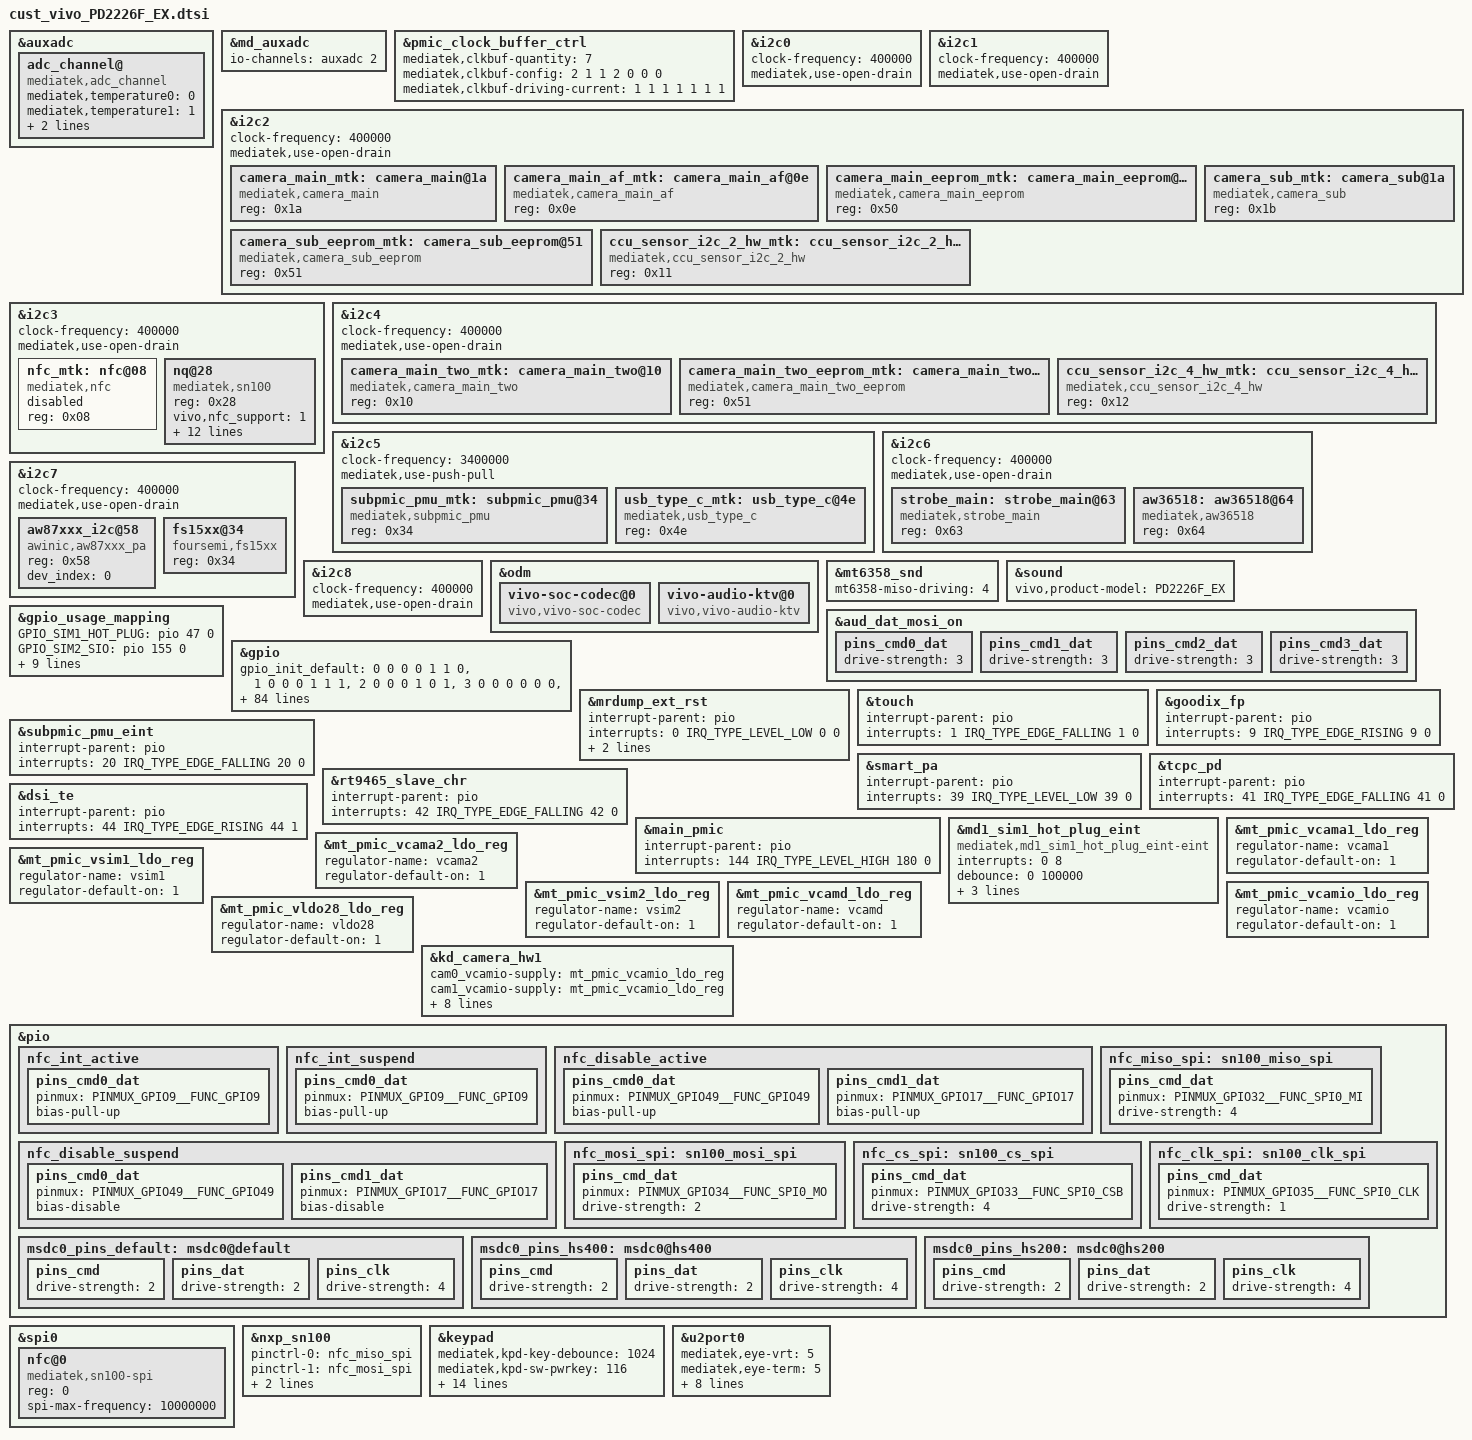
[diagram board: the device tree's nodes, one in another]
/*
 * Generated by MTK SP DrvGen Version: 3.5.160809 for MT6768.
 * 2022-04-25 19:38:39
 * Do Not Modify The File.
 * Copyright Mediatek Inc. (c) 2016.
*/

/*************************
 * ADC DTSI File
*************************/

&auxadc {
	adc_channel@ {
		compatible = "mediatek,adc_channel";
		mediatek,temperature0 = <0>;
		mediatek,temperature1 = <1>;
		mediatek,adc_fdd_rf_params_dynamic_custom_ch = <2>;
		status = "okay";
	};
};
&md_auxadc {
	io-channels = <&auxadc 2>;
};


/*************************
 * CLK_BUF DTSI File
*************************/

&pmic_clock_buffer_ctrl {
	mediatek,clkbuf-quantity = <7>;
	mediatek,clkbuf-config = <2 1 1 2 0 0 0>;
	mediatek,clkbuf-driving-current = <1 1 1 1 1 1 1>;
	status = "okay";
};


/*************************
 * I2C DTSI File
*************************/

&i2c0 {
	#address-cells = <1>;
	#size-cells = <0>;
	clock-frequency = <400000>;
	mediatek,use-open-drain;
};

&i2c1 {
	#address-cells = <1>;
	#size-cells = <0>;
	clock-frequency = <400000>;
	mediatek,use-open-drain;
};

&i2c2 {
	#address-cells = <1>;
	#size-cells = <0>;
	clock-frequency = <400000>;
	mediatek,use-open-drain;
	camera_main_mtk:camera_main@1a {
		compatible = "mediatek,camera_main";
		reg = <0x1a>;
		status = "okay";
	};
	camera_main_af_mtk:camera_main_af@0e {
		compatible = "mediatek,camera_main_af";
		reg = <0x0e>;
		status = "okay";
	};
	camera_main_eeprom_mtk:camera_main_eeprom@50 {
		compatible = "mediatek,camera_main_eeprom";
		reg = <0x50>;
		status = "okay";
	};
	camera_sub_mtk:camera_sub@1a {
		compatible = "mediatek,camera_sub";
		reg = <0x1b>;
		status = "okay";
	};
	camera_sub_eeprom_mtk:camera_sub_eeprom@51 {
		compatible = "mediatek,camera_sub_eeprom";
		reg = <0x51>;
		status = "okay";
	};

	ccu_sensor_i2c_2_hw_mtk:ccu_sensor_i2c_2_hw@11 {
		compatible = "mediatek,ccu_sensor_i2c_2_hw";
		reg = <0x11>;
		status = "okay";
	};

};

&i2c3 {
	#address-cells = <1>;
	#size-cells = <0>;
	clock-frequency = <400000>;
	mediatek,use-open-drain;
	nfc_mtk:nfc@08 {
		compatible = "mediatek,nfc";
		reg = <0x08>;
		status = "disable";
	};

};

&i2c4 {
	#address-cells = <1>;
	#size-cells = <0>;
	clock-frequency = <400000>;
	mediatek,use-open-drain;
	camera_main_two_mtk:camera_main_two@10 {
		compatible = "mediatek,camera_main_two";
		reg = <0x10>;
		status = "okay";
	};
	camera_main_two_eeprom_mtk:camera_main_two_eeprom@51 {
		compatible = "mediatek,camera_main_two_eeprom";
		reg = <0x51>;
		status = "okay";
	};

	ccu_sensor_i2c_4_hw_mtk:ccu_sensor_i2c_4_hw@12 {
		compatible = "mediatek,ccu_sensor_i2c_4_hw";
		reg = <0x12>;
		status = "okay";
	};

};

&i2c5 {
	#address-cells = <1>;
	#size-cells = <0>;
	clock-frequency = <3400000>;
	mediatek,use-push-pull;
	subpmic_pmu_mtk:subpmic_pmu@34 {
		compatible = "mediatek,subpmic_pmu";
		reg = <0x34>;
		status = "okay";
	};

	usb_type_c_mtk:usb_type_c@4e {
		compatible = "mediatek,usb_type_c";
		reg = <0x4e>;
		status = "okay";
	};

};

&i2c6 {
	#address-cells = <1>;
	#size-cells = <0>;
	clock-frequency = <400000>;
	mediatek,use-open-drain;
    strobe_main: strobe_main@63 {   //添加I2C设备
        compatible = "mediatek,strobe_main";
        reg = <0x63>;
        status = "okay";
    };
    aw36518: aw36518@64 {   //添加I2C设备
        compatible = "mediatek,aw36518";
        reg = <0x64>;
        status = "okay";
    };
};

&i2c7 {
	#address-cells = <1>;
	#size-cells = <0>;
	clock-frequency = <400000>;
	mediatek,use-open-drain;
};

&i2c8 {
	#address-cells = <1>;
	#size-cells = <0>;
	clock-frequency = <400000>;
	mediatek,use-open-drain;
};

/* xudong add for audio start */

&odm {
	vivo-soc-codec@0 {
		compatible = "vivo,vivo-soc-codec";
		status = "okay";
	};

	vivo-audio-ktv@0 {
		compatible = "vivo,vivo-audio-ktv";
		status = "okay";
	};
};

&i2c7 {
	aw87xxx_i2c@58 {
		compatible = "awinic,aw87xxx_pa";
		reg = <0x58>;
		dev_index= <0>;
		status = "okay";
	};
	fs15xx@34 {
 		compatible = "foursemi,fs15xx";
 		reg = <0x34>;
 		status = "okay";
 	};
};

/* yanghen add for audio end */
/* Audio add for modify miso driving */
/* 4:4mA, 8:8mA, 12:12mA, 16:16mA */
&mt6358_snd {
	mt6358-miso-driving = <4>;
};

&sound {
    vivo,product-model = "PD2226F_EX";
};

&aud_dat_mosi_on {
	pins_cmd0_dat {
		drive-strength = <3>;
	};
	pins_cmd1_dat {
		drive-strength = <3>;
	};
	pins_cmd2_dat {
		drive-strength = <3>;
	};
	pins_cmd3_dat {
		drive-strength = <3>;
	};
};
/* Audio add End */
/*************************
 * GPIO DTSI File
*************************/

&gpio_usage_mapping {
	GPIO_SIM1_HOT_PLUG = <&pio 47 0>; //GPIO_SIM1_HOT_PLUG gpio46
	GPIO_SIM2_SIO = <&pio 155 0>;
	GPIO_SIM2_SRST = <&pio 156 0>;
	GPIO_SIM2_SCLK = <&pio 157 0>;
	GPIO_SIM1_SCLK = <&pio 172 0>;
	GPIO_SIM1_SRST = <&pio 173 0>;
	GPIO_SIM1_SIO = <&pio 174 0>;
	GPIO_FDD_BAND_SUPPORT_DETECT_1ST_PIN = <&pio 23 0>;
	GPIO_FDD_BAND_SUPPORT_DETECT_2ND_PIN = <&pio 21 0>;
	GPIO_FDD_BAND_SUPPORT_DETECT_3RD_PIN = <&pio 10 0>;
	GPIO_FDD_BAND_SUPPORT_DETECT_4TH_PIN = <&pio 29 0>;
};

&gpio{
	gpio_init_default = <0 0 0 0 1 1 0>,
		<1 0 0 0 1 1 1>,
		<2 0 0 0 1 0 1>,
		<3 0 0 0 0 0 0>,//sub chg-int
		<4 0 0 0 1 0 0>,
		<5 0 0 0 1 1 0>,
		<6 0 0 0 0 0 0>,//main chg-int
		<7 0 0 0 1 0 0>,
		<8 0 0 0 1 0 0>,
		<9 0 0 0 1 0 0>,
		<10 0 0 0 1 1 0>,
		<11 1 0 0 1 0 0>,
		<12 0 0 0 0 0 1>,
		<13 2 0 0 0 0 0>,
		<14 2 1 0 0 0 0>,
		<15 2 1 0 0 0 0>,
		<16 2 1 0 0 0 0>,
		<17 0 0 0 1 0 1>,
		<18 0 0 0 1 1 1>,
		<19 0 0 0 1 1 1>,
		<20 0 0 0 1 1 1>,
		<21 0 0 0 1 1 0>,
		<22 0 1 0 1 0 0>,//sub chg enable
		<23 0 0 0 1 1 0>,
		<24 0 1 0 1 1 1>,//cam0 dvdd_en
		<25 0 1 0 1 0 0>,
		<26 0 1 0 1 0 0>,
		<27 0 1 0 1 0 0>,
		<28 0 1 0 1 0 0>,
		<29 0 0 0 1 1 0>,
		<30 0 1 0 0 0 0>,
		<31 0 0 0 1 0 0>,
		<32 7 1 0 0 0 0>,
		<33 7 0 0 1 0 0>,
		<34 7 0 0 1 0 0>,
		<35 7 0 0 1 0 0>,
		<36 2 1 0 0 0 0>,
		<37 2 1 0 0 0 0>,
		<38 2 1 0 0 0 0>,
		<39 0 0 0 1 1 1>,
		<40 2 0 0 1 0 0>,
		<41 0 0 0 1 1 1>,//cc logic int-gpio
		<42 0 0 0 1 1 1>,
		<43 1 1 0 0 0 0>,
		<44 1 0 0 1 0 0>,
		<45 0 1 0 0 0 0>,
		<46 0 0 0 0 0 0>,
		<47 1 0 0 0 0 1>,
		<48 1 0 0 1 1 1>,
		<49 1 0 0 1 1 1>,
		<50 1 0 0 0 0 1>,
		<51 1 0 0 0 0 1>,
		<52 1 0 0 1 0 0>,
		<53 1 0 0 1 0 0>,
		<54 1 0 0 1 0 0>,
		<55 1 0 0 1 0 0>,
		<56 1 0 0 1 0 0>,
		<57 1 0 0 1 0 0>,
		<58 0 0 0 1 0 0>,
		<59 1 0 0 1 0 0>,
		<60 1 0 0 1 0 0>,
		<61 1 0 0 1 0 0>,
		<62 1 0 0 1 0 0>,
		<63 1 0 0 1 0 0>,
		<64 1 0 0 1 0 0>,
		<65 1 0 0 1 0 0>,
		<66 1 0 0 1 0 0>,
		<67 1 0 0 1 0 0>,
		<68 1 0 0 1 0 0>,
		<69 1 0 0 1 0 0>,
		<70 1 0 0 1 0 0>,
		<71 1 0 0 1 0 0>,
		<72 1 0 0 1 0 0>,
		<73 1 0 0 1 0 0>,
		<74 1 0 0 1 0 0>,
		<75 1 0 0 1 0 0>,
		<76 1 0 0 1 0 0>,
		<77 1 0 0 1 0 0>,
		<78 0 0 0 1 1 0>,
		<79 0 0 0 1 0 0>,
		<80 0 0 0 1 0 0>,
		<81 2 0 0 1 1 1>,
		<82 1 0 0 1 1 1>,
		<83 1 0 0 1 1 1>,
		<84 2 0 0 1 1 1>,
		<85 2 0 0 1 0 0>,
		<86 2 1 0 0 0 0>,
		<87 2 1 0 0 0 0>,
		<88 2 1 0 0 0 0>,
		<89 1 0 0 0 0 1>,//flash i2c6 scl rear
		<90 1 0 0 0 0 1>,//flash i2c6 sda rear
		<91 0 0 0 1 1 0>,
		<92 0 1 0 1 1 1>,//CAM_FLASH_TORCH
		<93 1 0 0 1 1 0>,
		<94 0 1 0 0 0 0>,
		<95 1 0 0 1 1 0>,
		<96 1 1 0 0 0 0>,
		<97 0 1 0 0 0 0>,
		<98 0 1 0 0 0 0>,
		<99 1 1 0 0 0 0>,
		<100 1 0 0 1 0 1>,//cam0 mclk1
		<101 0 1 0 0 0 0>,
		<102 0 1 0 1 1 1>,//cam0 rst
		<103 1 0 0 0 0 1>,//cam0,1 i2c2 scl
		<104 1 0 0 0 0 1>,//cam0,1 i2c2 sda
		<105 1 0 0 0 0 1>,//cam2 i2c4 scl
		<106 1 0 0 0 0 1>,//cam2 i2c4 sda
		<107 0 1 0 0 0 0>,
		<108 1 0 0 1 0 1>,//cam1 mclk2
		<109 0 1 0 1 1 1>,//cam1 rst
		<110 0 1 0 0 0 0>,
		<111 1 0 0 1 0 1>,//cam2 mclk3
		<112 0 1 0 1 1 1>,//cam2 rst
		<113 0 0 0 1 0 0>,
		<114 0 0 0 1 0 0>,
		<115 0 0 0 1 0 0>,
		<116 0 0 0 1 0 0>,
		<117 0 0 0 1 0 0>,
		<118 0 0 0 1 0 0>,
		<119 0 0 0 1 0 0>,
		<120 0 0 0 1 0 0>,
		<121 0 0 0 1 0 0>,
		<134 1 0 0 1 0 1>,
		<135 1 1 0 0 0 0>,
		<136 1 1 0 0 0 0>,
		<137 1 1 0 0 0 0>,
		<138 1 1 0 0 0 0>,
		<139 1 1 0 0 0 0>,
		<140 1 0 0 1 0 0>,
		<141 1 0 0 1 0 0>,
		<142 1 0 0 1 0 0>,
		<143 1 0 0 1 0 0>,
		<144 1 0 0 1 0 0>,
		<145 1 1 0 0 0 0>,
		<146 1 1 0 0 0 0>,
		<147 1 1 0 0 0 0>,
		<148 1 1 0 0 0 0>,
		<149 1 1 0 0 0 0>,
		<150 0 1 0 1 1 1>,//cam0,1,2 avdd_en
		<151 0 1 0 0 0 0>,//usb oe
		<152 0 1 0 0 0 0>,//GPIO_FLASH_EN
		<153 0 1 0 0 0 0>,//GPIO_FLASH_STROBE
		<154 1 1 0 0 0 0>,
		<155 1 0 0 1 1 0>,
		<156 1 1 0 0 0 0>,
		<157 1 1 0 0 0 0>,
		<158 0 1 1 0 0 0>,//BATID_CTRL
		<159 0 1 0 0 0 0>,//usb sel
		<160 0 0 0 1 1 0>,
		<161 1 0 0 1 1 1>,
		<162 1 0 0 1 1 1>,
		<163 1 0 0 1 1 1>,
		<164 1 0 0 1 1 1>,
		<165 0 1 0 0 0 0>,
		<166 0 0 0 1 1 0>,
		<167 1 0 0 1 0 0>,
		<168 1 0 0 1 0 0>,
		<169 0 1 0 0 0 0>,
		<170 1 0 0 1 1 1>,
		<171 1 1 0 0 0 1>,
		<172 1 1 0 0 0 0>,
		<173 1 1 0 0 0 0>,
		<174 1 0 0 1 1 0>,
		<175 1 0 0 1 1 1>,
		<176 1 0 0 1 1 1>,
		<178 0 0 0 1 1 0>,
		<179 0 0 0 1 1 0>,
		<180 0 0 0 1 0 0>,
		<181 0 0 0 1 0 0>,
		<182 0 0 0 1 0 0>,
		<183 0 0 0 1 0 0>,
		<184 0 0 0 1 0 0>,
		<185 0 0 0 1 0 0>,
		<186 0 0 0 1 0 0>;
};


/*************************
 * EINT DTSI File
*************************/

#include <dt-bindings/interrupt-controller/irq.h>
#include <dt-bindings/interrupt-controller/arm-gic.h>

&mrdump_ext_rst {
	interrupt-parent = <&pio>;
	interrupts = <0 IRQ_TYPE_LEVEL_LOW 0 0>;
	deb-gpios = <&pio 0 0>;
	debounce = <512000>;
	status = "okay";
};

&touch {
	interrupt-parent = <&pio>;
	interrupts = <1 IRQ_TYPE_EDGE_FALLING 1 0>;
	status = "okay";
};

&goodix_fp {
	interrupt-parent = <&pio>;
	interrupts = <9 IRQ_TYPE_EDGE_RISING 9 0>;
	status = "okay";
};

&subpmic_pmu_eint {
	interrupt-parent = <&pio>;
	interrupts = <20 IRQ_TYPE_EDGE_FALLING 20 0>;
	status = "okay";
};

&smart_pa {
	interrupt-parent = <&pio>;
	interrupts = <39 IRQ_TYPE_LEVEL_LOW 39 0>;
	status = "okay";
};

&tcpc_pd {
	interrupt-parent = <&pio>;
	interrupts = <41 IRQ_TYPE_EDGE_FALLING 41 0>;
	status = "okay";
};

&rt9465_slave_chr {
	interrupt-parent = <&pio>;
	interrupts = <42 IRQ_TYPE_EDGE_FALLING 42 0>;
	status = "okay";
};

&dsi_te {
	interrupt-parent = <&pio>;
	interrupts = <44 IRQ_TYPE_EDGE_RISING 44 1>;
	status = "okay";
};

&main_pmic {
	interrupt-parent = <&pio>;
	interrupts = <144 IRQ_TYPE_LEVEL_HIGH 180 0>;
	status = "okay";
};



/*************************
 * MD1_EINT DTSI File
*************************/

&md1_sim1_hot_plug_eint {
	compatible = "mediatek,md1_sim1_hot_plug_eint-eint";
	interrupts = <0 8>;
	debounce = <0 100000>;
	dedicated = <0 0>;
	src_pin = <0 1>;
	sockettype = <0 0>;
	status = "okay";
};




/*************************
 * PMIC DTSI File
*************************/

&mt_pmic_vcama1_ldo_reg {
	regulator-name = "vcama1";
	regulator-default-on = <1>; /* 0:skip, 1: off, 2:on */
	status = "okay";
};
&mt_pmic_vcama2_ldo_reg {
	regulator-name = "vcama2";
	regulator-default-on = <1>; /* 0:skip, 1: off, 2:on */
	status = "okay";
};
&mt_pmic_vsim1_ldo_reg {
	regulator-name = "vsim1";
	regulator-default-on = <1>; /* 0:skip, 1: off, 2:on */
	status = "okay";
};
&mt_pmic_vsim2_ldo_reg {
	regulator-name = "vsim2";
	regulator-default-on = <1>; /* 0:skip, 1: off, 2:on */
	status = "okay";
};
&mt_pmic_vcamd_ldo_reg {
	regulator-name = "vcamd";
	regulator-default-on = <1>; /* 0:skip, 1: off, 2:on */
	status = "okay";
};
&mt_pmic_vcamio_ldo_reg {
	regulator-name = "vcamio";
	regulator-default-on = <1>; /* 0:skip, 1: off, 2:on */
	status = "okay";
};
&mt_pmic_vldo28_ldo_reg {
	regulator-name = "vldo28";
	regulator-default-on = <1>; /* 0:skip, 1: off, 2:on */
	status = "okay";
};

&kd_camera_hw1 {
	cam0_vcamio-supply = <&mt_pmic_vcamio_ldo_reg>;/*6358vcamio*/
	cam1_vcamio-supply = <&mt_pmic_vcamio_ldo_reg>;
	cam2_vcamio-supply = <&mt_pmic_vcamio_ldo_reg>;
	cam1_vcamd-supply = <&mt_pmic_vcamd_ldo_reg>;/*6358 DVDD*/
	cam0_vcamaf_def-supply = <&mt_pmic_vldo28_ldo_reg>; //vcamaf_def
	cam0_enable_sensor = "s5kjn1sq03pd2226f_mipi_raw";
	cam1_enable_sensor = "imx355pd2226f_mipi_raw s5k4h7pd2226f_mipi_raw";
	cam2_enable_sensor = "gc02m1pd2226f_mipi_raw ov02b10pd2226f_mipi_raw";
	status = "okay";
};

&camera_main_af_mtk {
	//vcamaf-supply = <&mt_pmic_vldo28_ldo_reg>;
};

/* NFC GPIO standardization begin*/
&pio {
	nfc_int_active: nfc_int_active {
		pins_cmd0_dat {
			pinmux = <PINMUX_GPIO9__FUNC_GPIO9>;
			bias-pull-up;
		};
	};
	nfc_int_suspend: nfc_int_suspend {
		pins_cmd0_dat {
			pinmux = <PINMUX_GPIO9__FUNC_GPIO9>;
			bias-pull-up;
		};
	};
	nfc_disable_active: nfc_disable_active {
		pins_cmd0_dat {
			pinmux = <PINMUX_GPIO49__FUNC_GPIO49>;
			bias-pull-up;
		};
		pins_cmd1_dat {
			pinmux = <PINMUX_GPIO17__FUNC_GPIO17>;
			bias-pull-up;
		};
	};
	nfc_disable_suspend: nfc_disable_suspend {
		pins_cmd0_dat {
			pinmux = <PINMUX_GPIO49__FUNC_GPIO49>;
			bias-disable;
		};
		pins_cmd1_dat {
			pinmux = <PINMUX_GPIO17__FUNC_GPIO17>;
			bias-disable;
		};
	};

};

&i2c3 {
	status = "okay";
	#address-cells = <1>;
	#size-cells = <0>;
	clock-frequency = <400000>;
	mediatek,use-open-drain;
	nq@28 {
		compatible = "mediatek,sn100";
		reg = <0x28>;
		vivo,nfc_support = <1>;
		vivo,boardversion_shift = <0>;
		vivo,boardversion_mask = <1>;
		vivo,boardversion_num = <1>;
		vivo,boardversions = "0";
		mediatek,nq-irq = <&pio 9 0x00>;
		mediatek,nq-ven = <&pio 49 0x00>;
		mediatek,nq-firm = <&pio 17 0x00>;
		//mediatek,nq-clkreq = <&pio 81 0x00>;
		interrupt-parent = <&pio>;
		interrupts = <5 0>;
		interrupt-names = "nfc_irq";
		pinctrl-names = "nfc_active", "nfc_suspend";
		pinctrl-0 = <&nfc_int_active &nfc_disable_active>;
		pinctrl-1 = <&nfc_int_suspend &nfc_disable_suspend>;
	};
};
/* NFC GPIO standardization end*/
/* NFC SPI standardization begin*/
&spi0 {
	#address-cells = <1>;
	#size-cells = <0>;
	nfc@0 {
		compatible = "mediatek,sn100-spi";
		reg = <0>;
		spi-max-frequency = <10000000>;
		status = "ok";
	};
};

&nxp_sn100 {
    status = "okay";
	pinctrl-names = "miso_spi","mosi_spi","cs_spi","clk_spi";
	pinctrl-0 = <&nfc_miso_spi>;
	pinctrl-1 = <&nfc_mosi_spi>;
	pinctrl-2 = <&nfc_cs_spi>;
	pinctrl-3 = <&nfc_clk_spi>;

};

&pio {
	nfc_miso_spi: sn100_miso_spi {
		pins_cmd_dat {
			pinmux = <PINMUX_GPIO32__FUNC_SPI0_MI>;
			drive-strength = <4>;
		};
	};
	nfc_mosi_spi: sn100_mosi_spi {
		pins_cmd_dat {
			pinmux = <PINMUX_GPIO34__FUNC_SPI0_MO>;
			drive-strength = <2>;
		};
	};
	nfc_cs_spi: sn100_cs_spi {
		pins_cmd_dat {
			pinmux = <PINMUX_GPIO33__FUNC_SPI0_CSB>;
			drive-strength = <4>;
			//bias-pull-up;
		};
	};
	nfc_clk_spi: sn100_clk_spi {
		pins_cmd_dat {
			pinmux = <PINMUX_GPIO35__FUNC_SPI0_CLK>;
			drive-strength = <1>;
		};
	};
};
/* NFC SPI standardization end*/

/*************************
 * KPD DTSI File
*************************/

&keypad {
	mediatek,kpd-key-debounce = <1024>;
	mediatek,kpd-sw-pwrkey = <116>;
	mediatek,kpd-hw-pwrkey = <8>;
	mediatek,kpd-sw-rstkey  = <114>;
	mediatek,kpd-hw-rstkey = <17>;
	mediatek,kpd-use-extend-type = <0>;
	/*HW Keycode [0~71] -> Linux Keycode*/
	mediatek,kpd-hw-map-num = <72>;
	mediatek,kpd-hw-init-map = <115 0 0 0 0 0 0 0 0 0 0 0 0 0 0 0 0 0 0 0 0 0 0 0 0 0 0 0 0 0 0 0 0 0 0 0 0 0 0 0 0 0 0 0 0 0 0 0 0 0 0 0 0 0 0 0 0 0 0 0 0 0 0 0 0 0 0 0 0 0 0 0 >;
	mediatek,kpd-pwrkey-eint-gpio = <0>;
	mediatek,kpd-pwkey-gpio-din  = <0>;
	mediatek,kpd-hw-dl-key0 = <17>;
	mediatek,kpd-hw-dl-key1 = <0>;
	mediatek,kpd-hw-dl-key2 = <8>;
	mediatek,kpd-hw-recovery-key = <17>;
	mediatek,kpd-hw-factory-key = <0>;
	status = "okay";
};

/* modify SoC mmc driver strength by hezerui start */
&pio {
	msdc0_pins_default: msdc0@default {
		pins_cmd {
			drive-strength = /bits/ 8 <2>;
		};
		pins_dat {
			drive-strength = /bits/ 8 <2>;
		};
		pins_clk {
			drive-strength = /bits/ 8 <4>;
		};
	};

	msdc0_pins_hs400: msdc0@hs400 {
		pins_cmd {
			drive-strength = /bits/ 8 <2>;
		};
		pins_dat {
			drive-strength = /bits/ 8 <2>;
		};
		pins_clk {
			drive-strength = /bits/ 8 <4>;
		};
	};

	msdc0_pins_hs200: msdc0@hs200 {
		pins_cmd {
			drive-strength = /bits/ 8 <2>;
		};
		pins_dat {
			drive-strength = /bits/ 8 <2>;
		};
		pins_clk {
			drive-strength = /bits/ 8 <4>;
		};
	};
};
/* modify SoC mmc driver strength by hezerui end */

//vivo panyaqin add for usb eye begin
&u2port0{
    mediatek,eye-vrt = <5>; /* 0~7 */
    mediatek,eye-term = <5>; /* 0~7 */
    mediatek,eye-rev6 = <3>; /* 0~3 */
    mediatek,eye-disc = <0xf>; /* 0~8 */
    mediatek,eye-intr = <0x1e>; /* 0~0xlf */
    mediatek,host-eye-vrt = <6>; /* 0~7 */
    mediatek,host-eye-term = <6>; /* 0~7 */
    mediatek,host-eye-rev6 = <3>; /* 0~3 */
    mediatek,host-eye-disc = <0xc>; /* 0~8 */
    mediatek,host-eye-intr = <0x14>; /* 0~0xlf */
};
//vivo panyaqin add for usb eye begin
